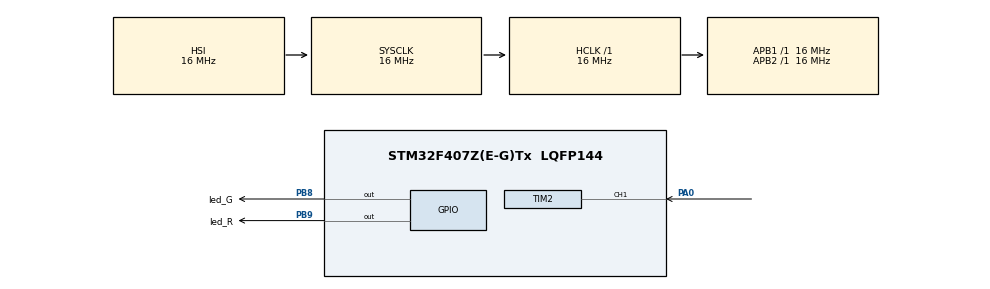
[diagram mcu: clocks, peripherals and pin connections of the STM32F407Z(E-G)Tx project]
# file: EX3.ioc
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Mcu.Family=STM32F4
Mcu.Name=STM32F407Z(E-G)Tx
Mcu.Package=LQFP144
NVIC.PriorityGroup=NVIC_PRIORITYGROUP_4
NVIC.TIM2_IRQn=true\:0\:0\:false\:false\:true\:true\:true\:true
NVIC.TIM5_IRQn=true\:0\:0\:false\:false\:true\:true\:true\:true
PA0-WKUP.Signal=S_TIM2_CH1_ETR
PA13.Mode=JTAG_5_pins
PA13.Signal=SYS_JTMS-SWDIO
PA14.Mode=JTAG_5_pins
PA14.Signal=SYS_JTCK-SWCLK
PA15.Mode=JTAG_5_pins
PA15.Signal=SYS_JTDI
PB3.Mode=JTAG_5_pins
PB3.Signal=SYS_JTDO-SWO
PB4.Mode=JTAG_5_pins
PB4.Signal=SYS_JTRST
PB8.GPIO_Label=led_G
PB8.GPIO_PuPd=GPIO_PULLDOWN
PB8.Signal=GPIO_Output
PB9.GPIO_Label=led_R
PB9.GPIO_PuPd=GPIO_PULLDOWN
PB9.Signal=GPIO_Output
ProjectManager.HeapSize=0x200
ProjectManager.StackSize=0x400
ProjectManager.TargetToolchain=MDK-ARM V5.32
RCC.AHBFreq_Value=16000000
RCC.APB1Freq_Value=16000000
RCC.APB2Freq_Value=16000000
RCC.CortexFreq_Value=16000000
RCC.HSE_VALUE=25000000
RCC.HSI_VALUE=16000000
RCC.LSE_VALUE=32768
RCC.SYSCLKFreq_VALUE=16000000
RCC.VCOOutputFreq_Value=192000000
SH.S_TIM2_CH1_ETR.0=TIM2_CH1,Input_Capture1_from_TI1
TIM2.Channel-Input_Capture1_from_TI1=TIM_CHANNEL_1
TIM2.Prescaler=16000-1
TIM5.AutoReloadPreload=TIM_AUTORELOAD_PRELOAD_ENABLE
TIM5.Period=100
TIM5.Prescaler=16000-1
VP_TIM2_VS_ClockSourceINT.Mode=Internal
VP_TIM5_VS_ClockSourceINT.Mode=Internal
board=custom

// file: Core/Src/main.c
/* USER CODE BEGIN Header */
/**
  ******************************************************************************
  * @file           : main.c
  * @brief          : General purpose Timer - Capture timer
  ******************************************************************************
  * Capture on Timer 2 channel 1
  *	basic in Timer 5 for Blinking LED G
	*
  * Hamed Saroli
  * Date : 2023-10-05
  ******************************************************************************
  */
/* USER CODE END Header */
#include "main.h"

TIM_HandleTypeDef htim2;
TIM_HandleTypeDef htim5;

void SystemClock_Config(void);
static void MX_GPIO_Init(void);
static void MX_TIM2_Init(void);
static void MX_TIM5_Init(void);

int main(void)
{
  /* MCU Configuration--------------------------------------------------------*/

  /* Reset of all peripherals, Initializes the Flash interface and the Systick. */
  HAL_Init();

  /* Configure the system clock */
  SystemClock_Config();

  /* Initialize all configured peripherals */
  MX_GPIO_Init();
  MX_TIM2_Init();
  MX_TIM5_Init();
  /* USER CODE BEGIN 2 */

	//HAL_TIM_IC_Start(&htim2,TIM_CHANNEL_1);
	HAL_TIM_IC_Start_IT(&htim2,TIM_CHANNEL_1);

	HAL_TIM_Base_Start_IT(&htim5);

  /* USER CODE END 2 */

  /* Infinite loop */
  while (1)
  {

  }
}

void SystemClock_Config(void)
{
  RCC_OscInitTypeDef RCC_OscInitStruct = {0};
  RCC_ClkInitTypeDef RCC_ClkInitStruct = {0};

  /** Configure the main internal regulator output voltage
  */
  __HAL_RCC_PWR_CLK_ENABLE();
  __HAL_PWR_VOLTAGESCALING_CONFIG(PWR_REGULATOR_VOLTAGE_SCALE1);

  /** Initializes the RCC Oscillators according to the specified parameters
  * in the RCC_OscInitTypeDef structure.
  */
  RCC_OscInitStruct.OscillatorType = RCC_OSCILLATORTYPE_HSI;
  RCC_OscInitStruct.HSIState = RCC_HSI_ON;
  RCC_OscInitStruct.HSICalibrationValue = RCC_HSICALIBRATION_DEFAULT;
  RCC_OscInitStruct.PLL.PLLState = RCC_PLL_NONE;
  if (HAL_RCC_OscConfig(&RCC_OscInitStruct) != HAL_OK)
  {
    Error_Handler();
  }

  /** Initializes the CPU, AHB and APB buses clocks
  */
  RCC_ClkInitStruct.ClockType = RCC_CLOCKTYPE_HCLK|RCC_CLOCKTYPE_SYSCLK
                              |RCC_CLOCKTYPE_PCLK1|RCC_CLOCKTYPE_PCLK2;
  RCC_ClkInitStruct.SYSCLKSource = RCC_SYSCLKSOURCE_HSI;
  RCC_ClkInitStruct.AHBCLKDivider = RCC_SYSCLK_DIV1;
  RCC_ClkInitStruct.APB1CLKDivider = RCC_HCLK_DIV1;
  RCC_ClkInitStruct.APB2CLKDivider = RCC_HCLK_DIV1;

  if (HAL_RCC_ClockConfig(&RCC_ClkInitStruct, FLASH_LATENCY_0) != HAL_OK)
  {
    Error_Handler();
  }
}

static void MX_TIM2_Init(void)
{

  TIM_ClockConfigTypeDef sClockSourceConfig = {0};
  TIM_MasterConfigTypeDef sMasterConfig = {0};
  TIM_IC_InitTypeDef sConfigIC = {0};

  htim2.Instance = TIM2;
  htim2.Init.Prescaler = 16000-1;
  htim2.Init.CounterMode = TIM_COUNTERMODE_UP;
  htim2.Init.Period = 4294967295;
  htim2.Init.ClockDivision = TIM_CLOCKDIVISION_DIV1;
  htim2.Init.AutoReloadPreload = TIM_AUTORELOAD_PRELOAD_DISABLE;
  if (HAL_TIM_Base_Init(&htim2) != HAL_OK)
  {
    Error_Handler();
  }
  sClockSourceConfig.ClockSource = TIM_CLOCKSOURCE_INTERNAL;
  if (HAL_TIM_ConfigClockSource(&htim2, &sClockSourceConfig) != HAL_OK)
  {
    Error_Handler();
  }
  if (HAL_TIM_IC_Init(&htim2) != HAL_OK)
  {
    Error_Handler();
  }
  sMasterConfig.MasterOutputTrigger = TIM_TRGO_RESET;
  sMasterConfig.MasterSlaveMode = TIM_MASTERSLAVEMODE_DISABLE;
  if (HAL_TIMEx_MasterConfigSynchronization(&htim2, &sMasterConfig) != HAL_OK)
  {
    Error_Handler();
  }
  sConfigIC.ICPolarity = TIM_INPUTCHANNELPOLARITY_RISING;
  sConfigIC.ICSelection = TIM_ICSELECTION_DIRECTTI;
  sConfigIC.ICPrescaler = TIM_ICPSC_DIV1;
  sConfigIC.ICFilter = 0;
  if (HAL_TIM_IC_ConfigChannel(&htim2, &sConfigIC, TIM_CHANNEL_1) != HAL_OK)
  {
    Error_Handler();
  }

}

static void MX_TIM5_Init(void)
{

  TIM_ClockConfigTypeDef sClockSourceConfig = {0};
  TIM_MasterConfigTypeDef sMasterConfig = {0};

  htim5.Instance = TIM5;
  htim5.Init.Prescaler = 16000-1;
  htim5.Init.CounterMode = TIM_COUNTERMODE_UP;
  htim5.Init.Period = 100;
  htim5.Init.ClockDivision = TIM_CLOCKDIVISION_DIV1;
  htim5.Init.AutoReloadPreload = TIM_AUTORELOAD_PRELOAD_ENABLE;
  if (HAL_TIM_Base_Init(&htim5) != HAL_OK)
  {
    Error_Handler();
  }
  sClockSourceConfig.ClockSource = TIM_CLOCKSOURCE_INTERNAL;
  if (HAL_TIM_ConfigClockSource(&htim5, &sClockSourceConfig) != HAL_OK)
  {
    Error_Handler();
  }
  sMasterConfig.MasterOutputTrigger = TIM_TRGO_RESET;
  sMasterConfig.MasterSlaveMode = TIM_MASTERSLAVEMODE_DISABLE;
  if (HAL_TIMEx_MasterConfigSynchronization(&htim5, &sMasterConfig) != HAL_OK)
  {
    Error_Handler();
  }

}

static void MX_GPIO_Init(void)
{
  GPIO_InitTypeDef GPIO_InitStruct = {0};

  /* GPIO Ports Clock Enable */
  __HAL_RCC_GPIOA_CLK_ENABLE();
  __HAL_RCC_GPIOB_CLK_ENABLE();

  /*Configure GPIO pin Output Level */
  HAL_GPIO_WritePin(GPIOB, led_G_Pin|led_R_Pin, GPIO_PIN_RESET);

  /*Configure GPIO pins : led_G_Pin led_R_Pin */
  GPIO_InitStruct.Pin = led_G_Pin|led_R_Pin;
  GPIO_InitStruct.Mode = GPIO_MODE_OUTPUT_PP;
  GPIO_InitStruct.Pull = GPIO_PULLDOWN;
  GPIO_InitStruct.Speed = GPIO_SPEED_FREQ_LOW;
  HAL_GPIO_Init(GPIOB, &GPIO_InitStruct);

}

void Error_Handler(void)
{
  __disable_irq();
  while (1)
  {
  }
}
